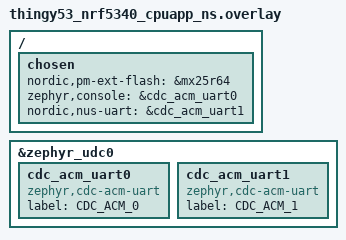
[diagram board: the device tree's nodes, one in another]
/*
 * Copyright (c) 2021 Nordic Semiconductor ASA
 *
 * SPDX-License-Identifier: LicenseRef-Nordic-5-Clause
 */

/ {
	chosen {
		nordic,pm-ext-flash = &mx25r64;
	};
};

/ {
	chosen {
		zephyr,console = &cdc_acm_uart0;
		nordic,nus-uart = &cdc_acm_uart1;
	};
};

&zephyr_udc0 {
	cdc_acm_uart0: cdc_acm_uart0 {
		compatible = "zephyr,cdc-acm-uart";
		label = "CDC_ACM_0";
	};

	cdc_acm_uart1: cdc_acm_uart1 {
		compatible = "zephyr,cdc-acm-uart";
		label = "CDC_ACM_1";
	};
};
